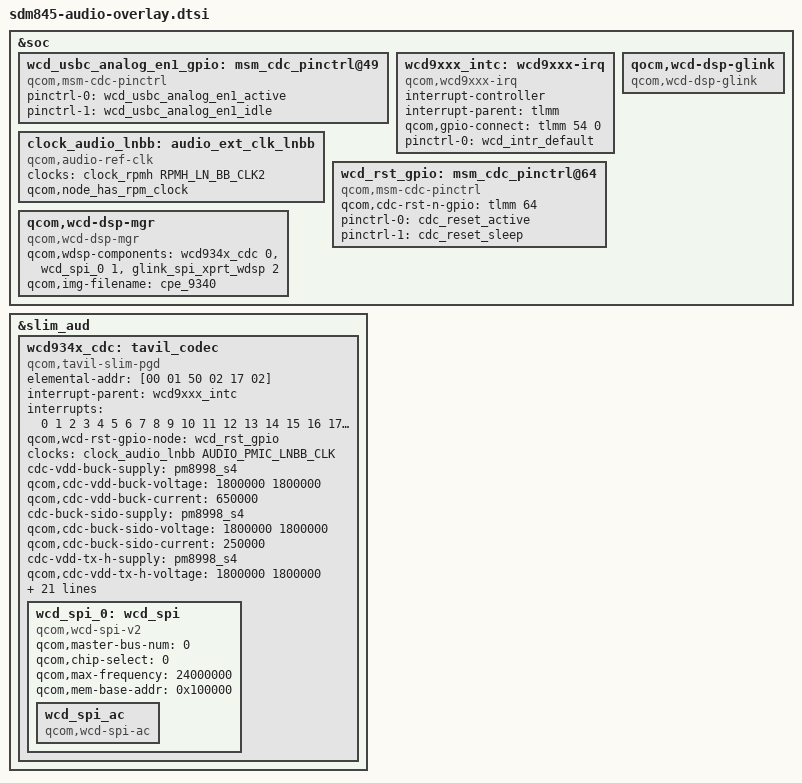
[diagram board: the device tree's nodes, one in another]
/*
 * Copyright (c) 2017, The Linux Foundation. All rights reserved.
 *
 * This program is free software; you can redistribute it and/or modify
 * it under the terms of the GNU General Public License version 2 and
 * only version 2 as published by the Free Software Foundation.
 *
 * This program is distributed in the hope that it will be useful,
 * but WITHOUT ANY WARRANTY; without even the implied warranty of
 * MERCHANTABILITY or FITNESS FOR A PARTICULAR PURPOSE.  See the
 * GNU General Public License for more details.
 */

#include "sdm845-wcd.dtsi"
#include <dt-bindings/clock/qcom,audio-ext-clk.h>

&soc {
	wcd_usbc_analog_en1_gpio: msm_cdc_pinctrl@49 {
		compatible = "qcom,msm-cdc-pinctrl";
		pinctrl-names = "aud_active", "aud_sleep";
		pinctrl-0 = <&wcd_usbc_analog_en1_active>;
		pinctrl-1 = <&wcd_usbc_analog_en1_idle>;
	};

	wcd9xxx_intc: wcd9xxx-irq {
		status = "ok";
		compatible = "qcom,wcd9xxx-irq";
		interrupt-controller;
		#interrupt-cells = <1>;
		interrupt-parent = <&tlmm>;
		qcom,gpio-connect = <&tlmm 54 0>;
		pinctrl-names = "default";
		pinctrl-0 = <&wcd_intr_default>;
	};

	clock_audio_lnbb: audio_ext_clk_lnbb {
		status = "ok";
		compatible = "qcom,audio-ref-clk";
		clock-names = "osr_clk";
		clocks = <&clock_rpmh RPMH_LN_BB_CLK2>;
		qcom,node_has_rpm_clock;
		#clock-cells = <1>;
	};

	wcd_rst_gpio: msm_cdc_pinctrl@64 {
		compatible = "qcom,msm-cdc-pinctrl";
		qcom,cdc-rst-n-gpio = <&tlmm 64 0>;
		pinctrl-names = "aud_active", "aud_sleep";
		pinctrl-0 = <&cdc_reset_active>;
		pinctrl-1 = <&cdc_reset_sleep>;
	};

	qocm,wcd-dsp-glink {
		compatible = "qcom,wcd-dsp-glink";
	};

	qcom,wcd-dsp-mgr {
		compatible = "qcom,wcd-dsp-mgr";
		qcom,wdsp-components = <&wcd934x_cdc 0>,
				       <&wcd_spi_0 1>,
				       <&glink_spi_xprt_wdsp 2>;
		qcom,img-filename = "cpe_9340";
	};
};

&slim_aud {
	wcd934x_cdc: tavil_codec {
		compatible = "qcom,tavil-slim-pgd";
		elemental-addr = [00 01 50 02 17 02];

		interrupt-parent = <&wcd9xxx_intc>;
		interrupts = <0 1 2 3 4 5 6 7 8 9 10 11 12 13 14 15 16
			      17 18 19 20 21 22 23 24 25 26 27 28 29
			      30 31>;

		qcom,wcd-rst-gpio-node = <&wcd_rst_gpio>;

		clock-names = "wcd_clk";
		clocks = <&clock_audio_lnbb AUDIO_PMIC_LNBB_CLK>;

		cdc-vdd-buck-supply = <&pm8998_s4>;
		qcom,cdc-vdd-buck-voltage = <1800000 1800000>;
		qcom,cdc-vdd-buck-current = <650000>;

		cdc-buck-sido-supply = <&pm8998_s4>;
		qcom,cdc-buck-sido-voltage = <1800000 1800000>;
		qcom,cdc-buck-sido-current = <250000>;

		cdc-vdd-tx-h-supply = <&pm8998_s4>;
		qcom,cdc-vdd-tx-h-voltage = <1800000 1800000>;
		qcom,cdc-vdd-tx-h-current = <25000>;

		cdc-vdd-rx-h-supply = <&pm8998_s4>;
		qcom,cdc-vdd-rx-h-voltage = <1800000 1800000>;
		qcom,cdc-vdd-rx-h-current = <25000>;

		cdc-vddpx-1-supply = <&pm8998_s4>;
		qcom,cdc-vddpx-1-voltage = <1800000 1800000>;
		qcom,cdc-vddpx-1-current = <10000>;

		qcom,cdc-static-supplies = "cdc-vdd-buck",
					   "cdc-buck-sido",
					   "cdc-vdd-tx-h",
					   "cdc-vdd-rx-h",
					   "cdc-vddpx-1";

		qcom,cdc-micbias1-mv = <1800>;
		qcom,cdc-micbias2-mv = <1800>;
		qcom,cdc-micbias3-mv = <1800>;
		qcom,cdc-micbias4-mv = <1800>;

		qcom,cdc-mclk-clk-rate = <9600000>;
		qcom,cdc-slim-ifd = "tavil-slim-ifd";
		qcom,cdc-slim-ifd-elemental-addr = [00 00 50 02 17 02];
		qcom,cdc-dmic-sample-rate = <4800000>;
		qcom,cdc-mad-dmic-rate = <600000>;

		qcom,wdsp-cmpnt-dev-name = "tavil_codec";

		wcd_spi_0: wcd_spi {
			compatible = "qcom,wcd-spi-v2";
			qcom,master-bus-num = <0>;
			qcom,chip-select = <0>;
			qcom,max-frequency = <24000000>;
			qcom,mem-base-addr = <0x100000>;

			wcd_spi_ac {
				compatible = "qcom,wcd-spi-ac";
			};
		};

	};
};
